VERSION "VER"

NS_ :

BS_:

BU_: E1

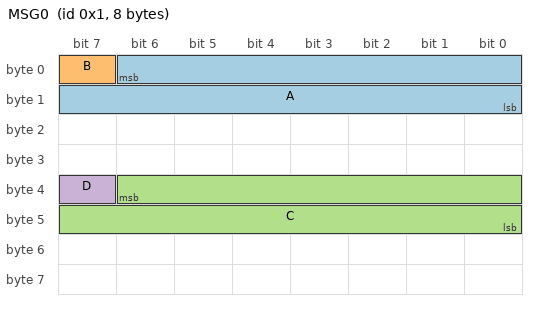
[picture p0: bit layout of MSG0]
BO_ 1 MSG0: 8 E1
 SG_ A : 6|15@0+ (1,0) [0|32768] ""  E1
 SG_ B : 7|1@0+ (1,0) [0|1] ""  E1
 SG_ C : 38|15@0+ (1,0) [0|32768] ""  E1
 SG_ D : 39|1@0+ (1,0) [0|1] ""  E1
